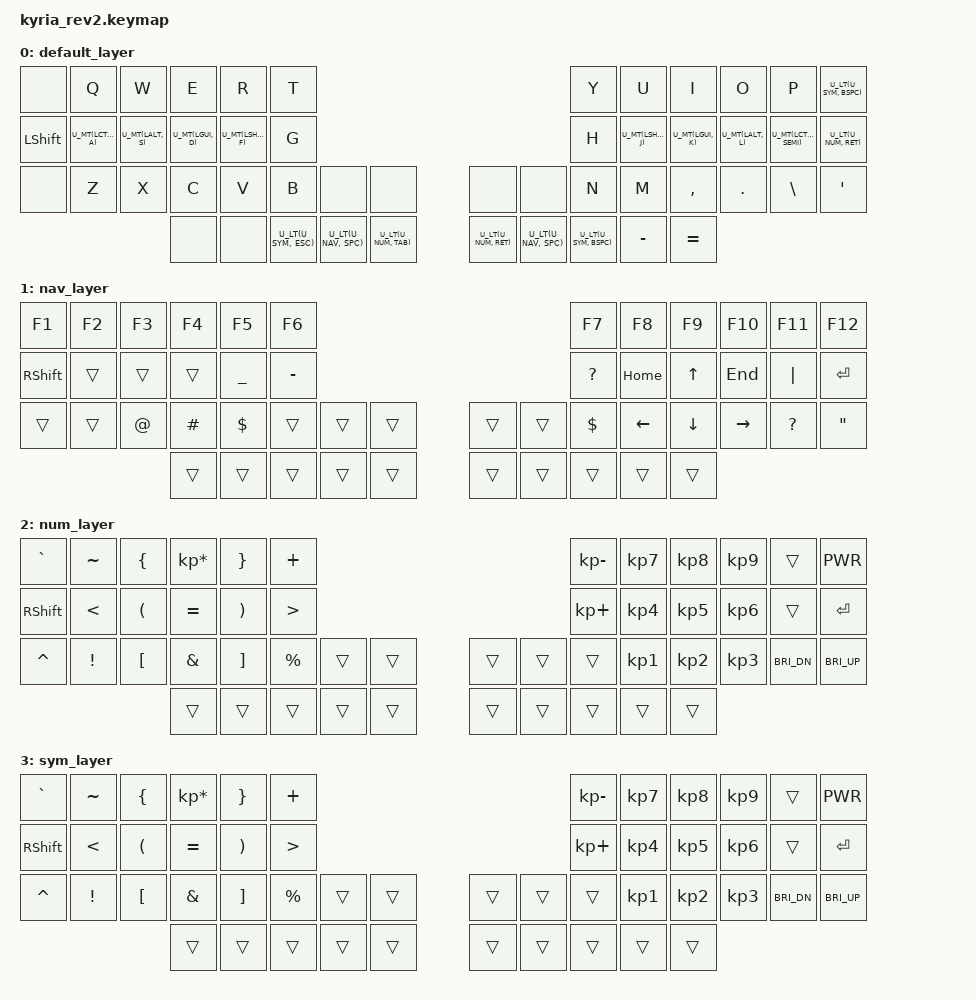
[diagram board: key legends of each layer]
/*
 * Copyright (c) 2020 The ZMK Contributors
 *
 * SPDX-License-Identifier: MIT
 */

#include <behaviors.dtsi>
#include <dt-bindings/zmk/keys.h>
#include <dt-bindings/zmk/bt.h>
// #include <dt-bindings/zmk/rgb.h>
#include <dt-bindings/zmk/outputs.h>
#include <dt-bindings/zmk/ext_power.h>
#include "miryoku_alt.dtsi"

/ {
	keymap {
		compatible = "zmk,keymap";

		default_layer {
			bindings = <
&none &kp Q &kp W &kp E    &kp R    &kp T                                                            &kp Y     &kp U    &kp I     &kp O   &kp P  U_LT(U_SYM, BSPC)
&kp LSHFT  U_MT(LCTRL, A)  U_MT(LALT, S)  U_MT(LGUI, D)  U_MT(LSHFT, F)  &kp G         &kp H  U_MT(LSHFT, J)  U_MT(LGUI, K)  U_MT(LALT, L)  U_MT(LCTRL, SEMI)   U_LT(U_NUM, RET) 
&none &kp Z &kp X &kp C    &kp V    &kp B     &none     &none                  &none    &none    &kp N     &kp M    &kp COMMA &kp DOT &kp BSLH  &kp SQT
                    &none   &none   U_LT(U_SYM, ESC)   U_LT(U_NAV, SPC)  U_LT(U_NUM, TAB)               U_LT(U_NUM, RET)  U_LT(U_NAV, SPC)  U_LT(U_SYM, BSPC)  &kp MINUS &kp EQUAL
		      >;

			// sensor-bindings = <&inc_dec_kp C_VOL_DN C_VOL_UP &inc_dec_kp DOWN UP>;
		};
		nav_layer {
// ---------------------------------------------------------------------------------------------------------------------------------------------------
// |   F1  |  F2 |  F3 |  F4  |  F5  |  F6  |                                                            |  F7  |   F8  |   F9  |  F10  |  F11 |  F12 |
// |       |     |     |      |   _  |  -   |                                                            |   £  |  HOME |   ⬆  |  END  |  pipe |  RET  |
// | SHIFT |     |  @  |  #   |  $   |      |       |       |                            |       |       |   $  |   ⬅  |   ⬇   |   ⮕  |   ?   |  "   |
//                     |  rot | OPT  | CTRL | CMD   | LOWER |                            | RAISE | SPACE | BSPC | OPT   |  rot   |
			bindings = <
&kp F1     &kp F2    &kp F3      &kp F4    &kp F5    &kp F6                                               &kp F7    &kp F8    &kp F9    &kp F10   &kp F11   &kp F12
&kp RSHIFT  &trans    &trans      &trans    &kp UNDER &kp MINUS                                            &kp QMARK &kp HOME  &kp UP    &kp END   &kp PIPE  &kp RET
&trans     &trans  &kp AT_SIGN &kp HASH  &kp DLLR  &trans  &trans    &trans       &trans    &trans        &kp DLLR  &kp LEFT  &kp DOWN  &kp RIGHT &kp QMARK &kp DQT
                      		  &trans   &trans   &trans   &trans   &trans              &trans   &trans   &trans   &trans   &trans
		      >;

			// sensor-bindings = <&inc_dec_kp C_VOL_DN C_VOL_UP &inc_dec_kp C_VOL_DN C_VOL_UP>;
		};
		num_layer {
// ---------------------------------------------------------------------------------------------------------------------------------------------------
// |    `  |  ~  |  {  |  *   |  }   |  +   |                                                            |  -   |   7   |   8   |   9  |       | POWER|
// | SHIFT |  <  |  (  |  =   |  )   |  >   |                                                            |  +   |   4   |   5   |   6  |   | RET
// |  ^  |  !  |  [  |  &   |  ]   |  %   |       |       |                            |       |       |      |   1   |   2   |   3  |   bright_dn |  bright_up   |
//                     |  rot | OPT  | CTRL | CMD   | LOWER |                            | RAISE | SPACE | BSPC |   0   |  rot   |
			bindings = <
&kp GRAVE   &kp TILDE &kp LBRC &kp KP_ASTERISK &kp RBRC  &kp PLUS                                              &kp KP_MINUS &kp KP_N7 &kp KP_N8 &kp KP_N9 &trans      &kp K_PWR
&kp RSHIFT   &kp LT    &kp LPAR &kp EQUAL       &kp RPAR  &kp GT                                               &kp KP_PLUS  &kp KP_N4 &kp KP_N5 &kp KP_N6 &trans      &kp RET
&kp CARET  &kp EXCL  &kp LBKT &kp AMPS        &kp RBKT  &kp PRCNT  &trans    &trans     &trans    &trans     &trans       &kp KP_N1 &kp KP_N2 &kp KP_N3 &kp C_BRI_DN  &kp C_BRI_UP
                    				&trans   &trans   &trans   &trans   &trans              &trans   &trans   &trans   &trans   &trans
		      >;

			// sensor-bindings = <&inc_dec_kp C_VOL_DN C_VOL_UP &inc_dec_kp PG_DN PG_UP>;
		};
		sym_layer {
// ---------------------------------------------------------------------------------------------------------------------------------------------------
// |    `  |  ~  |  {  |  *   |  }   |  +   |                                                            |  -   |   7   |   8   |   9  |       | POWER|
// | SHIFT |  <  |  (  |  =   |  )   |  >   |                                                            |  +   |   4   |   5   |   6  |   | RET
// |  ^  |  !  |  [  |  &   |  ]   |  %   |       |       |                            |       |       |      |   1   |   2   |   3  |   bright_dn |  bright_up   |
//                     |  rot | OPT  | CTRL | CMD   | LOWER |                            | RAISE | SPACE | BSPC |   0   |  rot   |
			bindings = <
&kp GRAVE   &kp TILDE &kp LBRC &kp KP_ASTERISK &kp RBRC  &kp PLUS                                              &kp KP_MINUS &kp KP_N7 &kp KP_N8 &kp KP_N9 &trans      &kp K_PWR
&kp RSHIFT   &kp LT    &kp LPAR &kp EQUAL       &kp RPAR  &kp GT                                               &kp KP_PLUS  &kp KP_N4 &kp KP_N5 &kp KP_N6 &trans      &kp RET
&kp CARET  &kp EXCL  &kp LBKT &kp AMPS        &kp RBKT  &kp PRCNT  &trans    &trans     &trans    &trans     &trans       &kp KP_N1 &kp KP_N2 &kp KP_N3 &kp C_BRI_DN  &kp C_BRI_UP
                   				    &trans   &trans   &trans   &trans   &trans              &trans   &trans   &trans   &trans   &trans
		      >;

			// sensor-bindings = <&inc_dec_kp C_VOL_DN C_VOL_UP &inc_dec_kp PG_DN PG_UP>;
		};

	};
};
